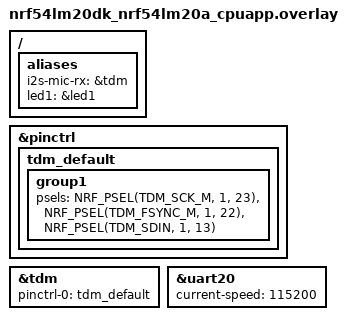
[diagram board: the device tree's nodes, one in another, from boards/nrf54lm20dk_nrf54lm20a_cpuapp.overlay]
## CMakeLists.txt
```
cmake_minimum_required(VERSION 3.20.0)
find_package(Zephyr REQUIRED HINTS $ENV{ZEPHYR_BASE})
project(10_beam_wakeword)

target_include_directories(app PRIVATE src src/nrf_edgeai_generated)

target_sources(app PRIVATE
  src/main.c
  src/wakeword.c
  src/nrf_edgeai_generated/nrf_edgeai_user_model.c
  src/dmic.c
)
```

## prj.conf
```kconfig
# nRF Edge AI
CONFIG_NRF_EDGEAI=y
CONFIG_NRF_AXON=y
CONFIG_NEWLIB_LIBC=y
CONFIG_FPU=y
CONFIG_NRF_AXON_INTERLAYER_BUFFER_SIZE=6700
CONFIG_NRF_AXON_PSUM_BUFFER_SIZE=0

# Peripherals
CONFIG_GPIO=y
CONFIG_I2S=y

# Logging / console
CONFIG_LOG=y
CONFIG_CONSOLE=y
CONFIG_SERIAL=y
CONFIG_ASSERT=y
CONFIG_UART_ASYNC_API=y
CONFIG_MAIN_STACK_SIZE=4096

# Wakeword app config
CONFIG_WW_PROBABILITY_THRESHOLD=700
CONFIG_WW_HISTORY_SIZE=6
CONFIG_WW_COUNT_THRESHOLD=4
```

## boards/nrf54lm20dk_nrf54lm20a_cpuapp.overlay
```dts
/*
 * INMP441 wiring:
 *   INMP441 SCK  -> DK pin 14 / P3.03  (TDM_SCK_M)
 *   INMP441 WS   -> DK pin 8  / P1.13  (TDM_FSYNC_M)
 *   INMP441 SD   -> DK pin 18 / P3.06  (TDM_SDIN)
 *   INMP441 VDD  -> 3V3
 *   INMP441 GND  -> GND
 *   INMP441 L/R  -> GND (left channel)
 */

/ {
	aliases {
		i2s-mic-rx = &tdm;
		led1 = &led1;
	};
};

&pinctrl {
	tdm_default: tdm_default {
		group1 {
			psels = <NRF_PSEL(TDM_SCK_M, 1, 23)>,
				<NRF_PSEL(TDM_FSYNC_M, 1, 22)>,
				<NRF_PSEL(TDM_SDIN, 1, 13)>;
		};
	};
};

&tdm {
	status = "okay";
	pinctrl-0 = <&tdm_default>;
	pinctrl-names = "default";
};

&uart20 {
	current-speed = <115200>;
};
```

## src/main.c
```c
/*
 * Copyright (c) 2026 Nordic Semiconductor ASA
 *
 * SPDX-License-Identifier: LicenseRef-Nordic-5-Clause
 */

#include <errno.h>
#include <stdbool.h>
#include <stddef.h>
#include <stdint.h>
#include <limits.h>

#include <zephyr/kernel.h>
#include <zephyr/device.h>
#include <zephyr/drivers/gpio.h>
#include <zephyr/logging/log.h>

#include "dmic.h"
#include "wakeword.h"

LOG_MODULE_REGISTER(main);

#define LED1_NODE DT_ALIAS(led1)
#define LED2_NODE DT_ALIAS(led2)
#define LED3_NODE DT_ALIAS(led3)

#if !DT_NODE_HAS_STATUS(LED1_NODE, okay)
#error "Unsupported board: led1 devicetree alias is not defined"
#endif

#if !DT_NODE_HAS_STATUS(LED2_NODE, okay)
#error "Unsupported board: led2 devicetree alias is not defined"
#endif

#if !DT_NODE_HAS_STATUS(LED3_NODE, okay)
#error "Unsupported board: led3 devicetree alias is not defined"
#endif

static const struct gpio_dt_spec led1 = GPIO_DT_SPEC_GET(LED1_NODE, gpios);
static const struct gpio_dt_spec led2 = GPIO_DT_SPEC_GET(LED2_NODE, gpios);
static const struct gpio_dt_spec led3 = GPIO_DT_SPEC_GET(LED3_NODE, gpios);

#define WW_LED_PULSE_MS       500
#define VAD_LATCH_WINDOW_MS   800

static bool ww_led2_on;
static bool ww_led3_on;
static int64_t ww_led_off_time_ms;
static int64_t last_vad_on_time_ms;
static int64_t vad_recent_until_ms;

/*
 * Stricter VAD tuning for less background-noise sensitivity.
 */
#define SILENCE_CHUNKS_OFF    35U
#define NOISE_INIT_RMS        25U
#define NOISE_MARGIN_ON       120U
#define NOISE_MARGIN_OFF      70U
#define NOISE_ALPHA_NUM       1U
#define NOISE_ALPHA_DEN       24U
#define VAD_ON_CHUNKS_REQ     2U

static bool speech_active;
static uint32_t silence_chunks;
static uint32_t speech_on_chunks;
static uint32_t noise_rms = NOISE_INIT_RMS;

struct chunk_stats {
    uint32_t rms;
    int16_t peak;
    uint32_t zcr;
    uint32_t est_hz;
};

static void trigger_ww_leds(bool arm_led3)
{
    (void)gpio_pin_set_dt(&led2, 1);
    ww_led2_on = true;

    if (arm_led3) {
        (void)gpio_pin_set_dt(&led3, 1);
        ww_led3_on = true;
    } else {
        (void)gpio_pin_set_dt(&led3, 0);
        ww_led3_on = false;
    }

    ww_led_off_time_ms = k_uptime_get() + WW_LED_PULSE_MS;
}

static void service_ww_leds(void)
{
    if (k_uptime_get() >= ww_led_off_time_ms) {
        if (ww_led2_on) {
            (void)gpio_pin_set_dt(&led2, 0);
            ww_led2_on = false;
        }
        if (ww_led3_on) {
            (void)gpio_pin_set_dt(&led3, 0);
            ww_led3_on = false;
        }
    }
}

static void set_vad_led(bool on)
{
    (void)gpio_pin_set_dt(&led1, on ? 1 : 0);

    if (on) {
        int64_t now = k_uptime_get();
        last_vad_on_time_ms = now;
        vad_recent_until_ms = now + VAD_LATCH_WINDOW_MS;
    }
}

static bool vad_recently_active(void)
{
    return (k_uptime_get() <= vad_recent_until_ms);
}

static uint32_t isqrt64(uint64_t x)
{
    uint64_t op = x;
    uint64_t res = 0;
    uint64_t one = 1ULL << 62;

    while (one > op) {
        one >>= 2;
    }

    while (one != 0U) {
        if (op >= (res + one)) {
            op -= (res + one);
            res = (res >> 1) + one;
        } else {
            res >>= 1;
        }
        one >>= 2;
    }

    return (uint32_t)res;
}

static void analyze_chunk(const int16_t *samples, size_t count,
              struct chunk_stats *stats)
{
    uint64_t energy = 0;
    int16_t peak_abs = 0;
    uint32_t crossings = 0;
    bool was_positive;

    if ((samples == NULL) || (stats == NULL) || (count == 0U)) {
        if (stats != NULL) {
            stats->rms = 0;
            stats->peak = 0;
            stats->zcr = 0;
            stats->est_hz = 0;
        }
        return;
    }

    was_positive = (samples[0] >= 0);

    for (size_t i = 0; i < count; i++) {
        int32_t s = samples[i];
        int32_t abs32 = (s < 0) ? -s : s;

        if (abs32 > INT16_MAX) {
            abs32 = INT16_MAX;
        }

        energy += (uint64_t)((int64_t)s * (int64_t)s);

        if ((int16_t)abs32 > peak_abs) {
            peak_abs = (int16_t)abs32;
        }

        if (i > 0U) {
            bool is_positive = (s >= 0);
            if (is_positive != was_positive) {
                crossings++;
            }
            was_positive = is_positive;
        }
    }

    stats->rms = isqrt64(energy / count);
    stats->peak = peak_abs;
    stats->zcr = crossings;
    stats->est_hz = (count > 1U) ? ((crossings * DMIC_PCM_RATE) / (2U * count)) : 0U;
}

static uint32_t vad_th_on(void)
{
    return noise_rms + NOISE_MARGIN_ON;
}

static uint32_t vad_th_off(void)
{
    return noise_rms + NOISE_MARGIN_OFF;
}

static void update_noise_estimate(uint32_t beam_rms)
{
    uint32_t th_off = vad_th_off();

    if (beam_rms < th_off) {
        int32_t diff = (int32_t)beam_rms - (int32_t)noise_rms;
        int32_t step = (diff * (int32_t)NOISE_ALPHA_NUM) / (int32_t)NOISE_ALPHA_DEN;
        noise_rms = (uint32_t)((int32_t)noise_rms + step);
    }
}

static void update_vad(uint32_t beam_rms)
{
    uint32_t th_on = vad_th_on();
    uint32_t th_off = vad_th_off();

    if (!speech_active) {
        if (beam_rms > th_on) {
            speech_on_chunks++;
            if (speech_on_chunks >= VAD_ON_CHUNKS_REQ) {
                speech_active = true;
                silence_chunks = 0;
                speech_on_chunks = 0;
                set_vad_led(true);
                LOG_INF("VAD: speech start (rms=%u noise=%u th_on=%u)",
                    beam_rms, noise_rms, th_on);
            }
        } else {
            speech_on_chunks = 0;
        }
        return;
    }

    if (beam_rms < th_off) {
        silence_chunks++;
        if (silence_chunks >= SILENCE_CHUNKS_OFF) {
            speech_active = false;
            silence_chunks = 0;
            speech_on_chunks = 0;
            set_vad_led(false);
            LOG_INF("VAD: speech stop (rms=%u noise=%u th_off=%u)",
                beam_rms, noise_rms, th_off);
        }
    } else {
        silence_chunks = 0;
        last_vad_on_time_ms = k_uptime_get();
        vad_recent_until_ms = last_vad_on_time_ms + VAD_LATCH_WINDOW_MS;
    }
}

int main(void)
{
    int err;

    if (!gpio_is_ready_dt(&led1)) {
        LOG_ERR("LED1 device is not ready");
        return -ENODEV;
    }

    if (!gpio_is_ready_dt(&led2)) {
        LOG_ERR("LED2 device is not ready");
        return -ENODEV;
    }

    if (!gpio_is_ready_dt(&led3)) {
        LOG_ERR("LED3 device is not ready");
        return -ENODEV;
    }

    err = gpio_pin_configure_dt(&led1, GPIO_OUTPUT_INACTIVE);
    if (err < 0) {
        LOG_ERR("Failed to configure LED1 (err %d)", err);
        return err;
    }

    err = gpio_pin_configure_dt(&led2, GPIO_OUTPUT_INACTIVE);
    if (err < 0) {
        LOG_ERR("Failed to configure LED2 (err %d)", err);
        return err;
    }

    err = gpio_pin_configure_dt(&led3, GPIO_OUTPUT_INACTIVE);
    if (err < 0) {
        LOG_ERR("Failed to configure LED3 (err %d)", err);
        return err;
    }

    set_vad_led(false);
    (void)gpio_pin_set_dt(&led2, 0);
    (void)gpio_pin_set_dt(&led3, 0);
    ww_led_off_time_ms = 0;
    last_vad_on_time_ms = 0;
    vad_recent_until_ms = 0;
    speech_on_chunks = 0;

    err = dmic_init();
    if (err) {
        return err;
    }

    err = ww_init();
    if (err) {
        return err;
    }

    LOG_INF("Initialization completed (LED1=VAD, LED2=WW, LED3=WW+recent VAD, stricter VAD)");

    err = dmic_start();
    if (err < 0) {
        LOG_ERR("Failed to start audio capture (err %d)", err);
        return err;
    }

    while (true) {
        void *audio_buffer;
        size_t audio_buffer_size;
        bool ww_detected;
        struct chunk_stats stats_bf;

        const int32_t read_timeout = 100;

        service_ww_leds();

        err = dmic_read(&audio_buffer, &audio_buffer_size, read_timeout);
        if (err < 0) {
            LOG_ERR("Failed to read audio (err %d)", err);
            return err;
        }

        analyze_chunk((const int16_t *)audio_buffer,
                  audio_buffer_size / DMIC_SAMPLE_BYTES,
                  &stats_bf);
        update_noise_estimate(stats_bf.rms);
        update_vad(stats_bf.rms);

        err = ww_process((uint8_t *)audio_buffer,
                 (uint16_t)(audio_buffer_size / DMIC_SAMPLE_BYTES),
                 &ww_detected);
        if (err == -EBUSY) {
            continue;
        } else if (err < 0) {
            LOG_ERR("Wakeword detection failed (err %d)", err);
            return err;
        }

        if (ww_detected) {
            bool led3_should_pulse = vad_recently_active();
            LOG_INF("Wake word detected (led3=%d)", led3_should_pulse ? 1 : 0);
            trigger_ww_leds(led3_should_pulse);
        }
    }

    return 0;
}
```

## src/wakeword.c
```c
/*
 * Copyright (c) 2026 Nordic Semiconductor ASA
 *
 * SPDX-License-Identifier: LicenseRef-Nordic-5-Clause
 */

#include <stddef.h>
#include <stdint.h>
#include <string.h>
#include <errno.h>

#include <zephyr/kernel.h>
#include <zephyr/logging/log.h>
#include <nrf_edgeai/nrf_edgeai.h>

#include "dmic.h"
#include "wakeword.h"
#include "nrf_edgeai_generated/nrf_edgeai_user_model.h"

LOG_MODULE_REGISTER(ww);

static nrf_edgeai_t *ww_model;
static uint16_t ww_input_samples;
static int16_t ww_input_buffer[512];
static uint16_t ww_input_fill;

BUILD_ASSERT(CONFIG_WW_HISTORY_SIZE <= 32, "WW_HISTORY_SIZE must fit in uint32_t");

int ww_init(void)
{
    ww_model = nrf_edgeai_user_model();
    __ASSERT_NO_MSG(ww_model);

    nrf_edgeai_err_t err = nrf_edgeai_init(ww_model);
    if (err) {
        LOG_ERR("Model initialization failed (err %d)", err);
        return -ENOENT;
    }

    ww_input_samples = nrf_edgeai_input_window_size(ww_model);
    __ASSERT_NO_MSG(ww_input_samples > 0);
    __ASSERT_NO_MSG(ww_input_samples <= ARRAY_SIZE(ww_input_buffer));

    ww_input_fill = 0U;

    LOG_INF("Wakeword initialized, input_window=%u samples", ww_input_samples);
    return 0;
}

static bool ww_postprocess(void)
{
    static uint32_t ww_count;
    static uint32_t ww_history;
    static int64_t last_detect_time_ms;

    const float ww_threshold = CONFIG_WW_PROBABILITY_THRESHOLD / 1000.f;
    const int64_t now_ms = k_uptime_get();
    const int64_t cooldown_ms = 1200;

    const uint16_t predicted_class = ww_model->decoded_output.classif.predicted_class;
    const float class_probability =
        ww_model->decoded_output.classif.probabilities.p_f32[predicted_class];
    const bool ww_frame_positive = class_probability > ww_threshold;

    const bool oldest_entry = (bool)(ww_history & BIT(CONFIG_WW_HISTORY_SIZE - 1));

    ww_count = ww_count + ww_frame_positive - oldest_entry;
    ww_history = (ww_history << 1) | ww_frame_positive;

    LOG_DBG("postprocess: pred=%u prob=%f count=%u",
        predicted_class, (double)class_probability, ww_count);

    if (ww_count >= CONFIG_WW_COUNT_THRESHOLD) {
        ww_count = 0U;
        ww_history = 0U;

        if ((now_ms - last_detect_time_ms) < cooldown_ms) {
            return false;
        }

        last_detect_time_ms = now_ms;
        return true;
    }

    return false;
}

static int ww_run_window(bool *const ww_detected)
{
    nrf_edgeai_err_t err;

    err = nrf_edgeai_feed_inputs(ww_model, ww_input_buffer, ww_input_samples);
    if (err == NRF_EDGEAI_ERR_INPROGRESS) {
        return -EBUSY;
    } else if (err) {
        LOG_ERR("Failed to feed inputs (err %d)", err);
        return -EPERM;
    }

    err = nrf_edgeai_run_inference(ww_model);
    if (err == NRF_EDGEAI_ERR_INPROGRESS) {
        return -EBUSY;
    } else if (err) {
        LOG_ERR("Failed to run inference (err %d)", err);
        return -EPERM;
    }

    *ww_detected = ww_postprocess();
    return 0;
}

int ww_process(uint8_t *const audio_buffer, const uint16_t num_samples, bool *const ww_detected)
{
    const int16_t *samples = (const int16_t *)audio_buffer;
    uint16_t consumed = 0U;

    __ASSERT_NO_MSG(audio_buffer);
    __ASSERT_NO_MSG(ww_detected);

    *ww_detected = false;

    while (consumed < num_samples) {
        const uint16_t space_left = ww_input_samples - ww_input_fill;
        const uint16_t copy_now =
            MIN((uint16_t)(num_samples - consumed), space_left);

        memcpy(&ww_input_buffer[ww_input_fill],
               &samples[consumed],
               copy_now * sizeof(int16_t));

        ww_input_fill += copy_now;
        consumed += copy_now;

        if (ww_input_fill == ww_input_samples) {
            int ret = ww_run_window(ww_detected);
            ww_input_fill = 0U;

            if (ret == -EBUSY) {
                free_dmic_buffer(audio_buffer);
                return -EBUSY;
            } else if (ret < 0) {
                free_dmic_buffer(audio_buffer);
                return ret;
            }

            if (*ww_detected) {
                free_dmic_buffer(audio_buffer);
                return 0;
            }
        }
    }

    free_dmic_buffer(audio_buffer);
    return 0;
}
```

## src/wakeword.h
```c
/*
 * Copyright (c) 2026 Nordic Semiconductor ASA
 *
 * SPDX-License-Identifier: LicenseRef-Nordic-5-Clause
 */

#ifndef __WAKEWORD_H__
#define __WAKEWORD_H__

#include <stdbool.h>
#include <stdint.h>

#ifdef __cplusplus
extern "C" {
#endif

int ww_init(void);
int ww_process(uint8_t *const audio_buffer, const uint16_t num_samples, bool *const ww_detected);

#ifdef __cplusplus
}
#endif

#endif /* __WAKEWORD_H__ */
```
